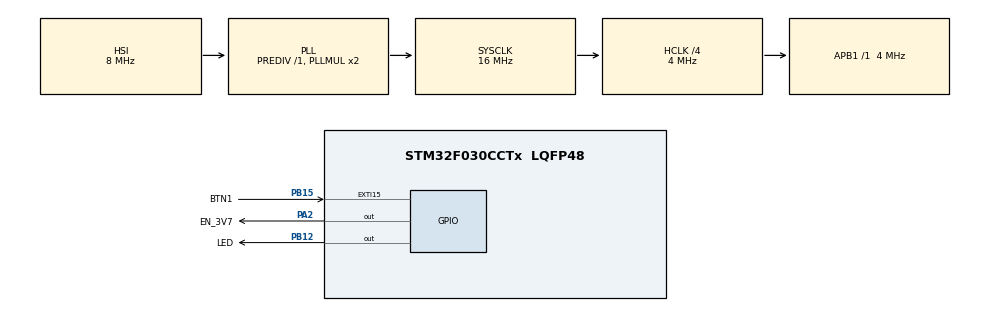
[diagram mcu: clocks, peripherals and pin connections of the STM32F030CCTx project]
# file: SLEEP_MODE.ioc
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Mcu.Family=STM32F0
Mcu.Name=STM32F030CCTx
Mcu.Package=LQFP48
NVIC.EXTI4_15_IRQn=true\:0\:0\:false\:false\:true\:true\:true\:true
PA13.Mode=Serial_Wire
PA13.Signal=SYS_SWDIO
PA14.Mode=Serial_Wire
PA14.Signal=SYS_SWCLK
PA2.GPIO_Label=EN_3V7
PA2.GPIO_PuPd=GPIO_NOPULL
PA2.GPIO_Speed=GPIO_SPEED_FREQ_LOW
PA2.PinState=GPIO_PIN_SET
PA2.Signal=GPIO_Output
PB12.GPIO_Label=LED
PB12.Signal=GPIO_Output
PB15.GPIO_Label=BTN1
PB15.GPIO_ModeDefaultEXTI=GPIO_MODE_IT_FALLING
PB15.GPIO_PuPd=GPIO_PULLUP
PB15.Signal=GPXTI15
ProjectManager.HeapSize=0x200
ProjectManager.StackSize=0x400
ProjectManager.TargetToolchain=STM32CubeIDE
RCC.AHBCLKDivider=RCC_SYSCLK_DIV4
RCC.AHBFreq_Value=4000000
RCC.APB1Freq_Value=4000000
RCC.APB1TimFreq_Value=4000000
RCC.HCLKFreq_Value=4000000
RCC.SYSCLKFreq_VALUE=16000000
RCC.SYSCLKSource=RCC_SYSCLKSOURCE_PLLCLK
board=custom

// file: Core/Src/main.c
/* USER CODE BEGIN Header */
/**
  ******************************************************************************
  * @file           : main.c
  * @brief          : Main program body
  ******************************************************************************
  * @attention
  *
  * Copyright (c) 2024 STMicroelectronics.
  * All rights reserved.
  *
  * This software is licensed under terms that can be found in the LICENSE file
  * in the root directory of this software component.
  * If no LICENSE file comes with this software, it is provided AS-IS.
  *
  ******************************************************************************
  */
/* USER CODE END Header */
#include "main.h"

/* USER CODE BEGIN PV */
uint8_t state=0;
/* USER CODE END PV */

void SystemClock_Config(void);
static void MX_GPIO_Init(void);

int main(void)
{

  /* MCU Configuration--------------------------------------------------------*/

  /* Reset of all peripherals, Initializes the Flash interface and the Systick. */
  HAL_Init();

  /* Configure the system clock */
  SystemClock_Config();

  /* Initialize all configured peripherals */
  MX_GPIO_Init();

  /* Infinite loop */
  while (1)
  {

    /* USER CODE BEGIN 3 */
	  state = 0; //Yendo a SLEEP MODE en 5 segundos
	  HAL_GPIO_WritePin(LED_GPIO_Port, LED_Pin, SET);
	  HAL_Delay(3000);

	  HAL_SuspendTick();//antes de entrar al modo sleep debe suspenderse los ticks
	  HAL_GPIO_WritePin(LED_GPIO_Port, LED_Pin, RESET);

	  //AQUI ENTRO AL MODO SLEEP
	  //el regulador principal encendido y el despertador
	  HAL_PWR_EnterSLEEPMode(PWR_MAINREGULATOR_ON, PWR_SLEEPENTRY_WFI);//interrupt for wake up

	  HAL_ResumeTick();//CPU en modo suspencion
	  state = 1;//Woke up form SLEEP

	  for(uint8_t i=0; i<20; i++){
		  HAL_GPIO_TogglePin(LED_GPIO_Port, LED_Pin);
		  HAL_Delay(150);
	  }

  }
  /* USER CODE END 3 */
}

void SystemClock_Config(void)
{
  RCC_OscInitTypeDef RCC_OscInitStruct = {0};
  RCC_ClkInitTypeDef RCC_ClkInitStruct = {0};

  /** Initializes the RCC Oscillators according to the specified parameters
  * in the RCC_OscInitTypeDef structure.
  */
  RCC_OscInitStruct.OscillatorType = RCC_OSCILLATORTYPE_HSI;
  RCC_OscInitStruct.HSIState = RCC_HSI_ON;
  RCC_OscInitStruct.HSICalibrationValue = RCC_HSICALIBRATION_DEFAULT;
  RCC_OscInitStruct.PLL.PLLState = RCC_PLL_ON;
  RCC_OscInitStruct.PLL.PLLSource = RCC_PLLSOURCE_HSI;
  RCC_OscInitStruct.PLL.PLLMUL = RCC_PLL_MUL2;
  RCC_OscInitStruct.PLL.PREDIV = RCC_PREDIV_DIV1;
  if (HAL_RCC_OscConfig(&RCC_OscInitStruct) != HAL_OK)
  {
    Error_Handler();
  }

  /** Initializes the CPU, AHB and APB buses clocks
  */
  RCC_ClkInitStruct.ClockType = RCC_CLOCKTYPE_HCLK|RCC_CLOCKTYPE_SYSCLK
                              |RCC_CLOCKTYPE_PCLK1;
  RCC_ClkInitStruct.SYSCLKSource = RCC_SYSCLKSOURCE_PLLCLK;
  RCC_ClkInitStruct.AHBCLKDivider = RCC_SYSCLK_DIV4;
  RCC_ClkInitStruct.APB1CLKDivider = RCC_HCLK_DIV1;

  if (HAL_RCC_ClockConfig(&RCC_ClkInitStruct, FLASH_LATENCY_0) != HAL_OK)
  {
    Error_Handler();
  }
}

static void MX_GPIO_Init(void)
{
  GPIO_InitTypeDef GPIO_InitStruct = {0};

  /* GPIO Ports Clock Enable */
  __HAL_RCC_GPIOA_CLK_ENABLE();
  __HAL_RCC_GPIOB_CLK_ENABLE();

  /*Configure GPIO pin Output Level */
  HAL_GPIO_WritePin(EN_3V7_GPIO_Port, EN_3V7_Pin, GPIO_PIN_SET);

  /*Configure GPIO pin Output Level */
  HAL_GPIO_WritePin(LED_GPIO_Port, LED_Pin, GPIO_PIN_RESET);

  /*Configure GPIO pin : EN_3V7_Pin */
  GPIO_InitStruct.Pin = EN_3V7_Pin;
  GPIO_InitStruct.Mode = GPIO_MODE_OUTPUT_PP;
  GPIO_InitStruct.Pull = GPIO_NOPULL;
  GPIO_InitStruct.Speed = GPIO_SPEED_FREQ_LOW;
  HAL_GPIO_Init(EN_3V7_GPIO_Port, &GPIO_InitStruct);

  /*Configure GPIO pin : LED_Pin */
  GPIO_InitStruct.Pin = LED_Pin;
  GPIO_InitStruct.Mode = GPIO_MODE_OUTPUT_PP;
  GPIO_InitStruct.Pull = GPIO_NOPULL;
  GPIO_InitStruct.Speed = GPIO_SPEED_FREQ_LOW;
  HAL_GPIO_Init(LED_GPIO_Port, &GPIO_InitStruct);

  /*Configure GPIO pin : BTN1_Pin */
  GPIO_InitStruct.Pin = BTN1_Pin;
  GPIO_InitStruct.Mode = GPIO_MODE_IT_FALLING;
  GPIO_InitStruct.Pull = GPIO_PULLUP;
  HAL_GPIO_Init(BTN1_GPIO_Port, &GPIO_InitStruct);

  /* EXTI interrupt init*/
  HAL_NVIC_SetPriority(EXTI4_15_IRQn, 0, 0);
  HAL_NVIC_EnableIRQ(EXTI4_15_IRQn);

}

void Error_Handler(void)
{
  __disable_irq();
  while (1)
  {
  }
}
